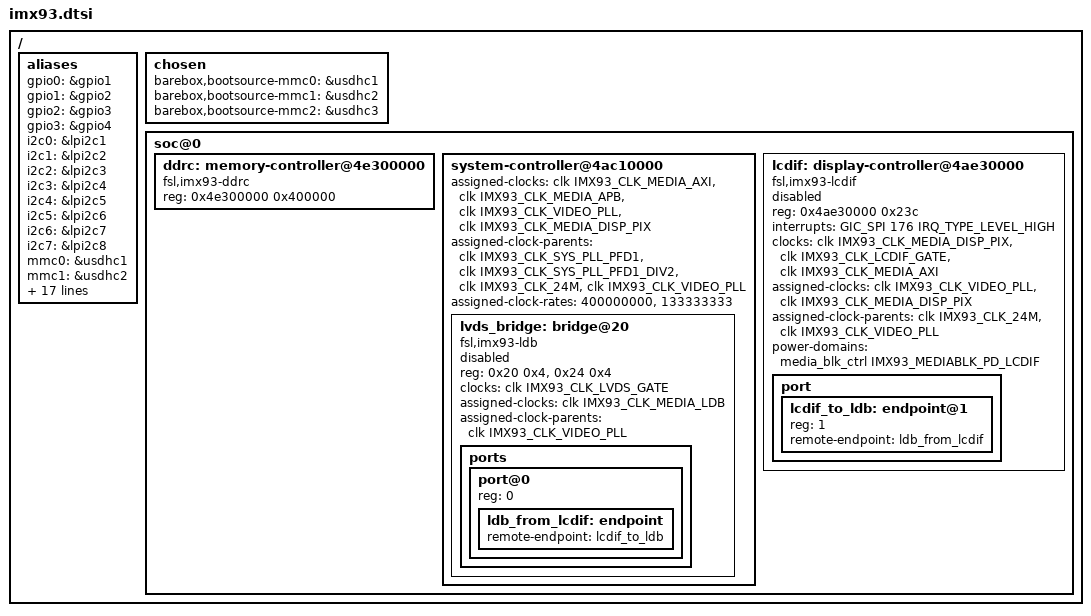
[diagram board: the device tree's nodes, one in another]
// SPDX-License-Identifier: (GPL-2.0+ OR MIT)
/ {
	aliases {
		gpio0 = &gpio1;
		gpio1 = &gpio2;
		gpio2 = &gpio3;
		gpio3 = &gpio4;
		i2c0 = &lpi2c1;
		i2c1 = &lpi2c2;
		i2c2 = &lpi2c3;
		i2c3 = &lpi2c4;
		i2c4 = &lpi2c5;
		i2c5 = &lpi2c6;
		i2c6 = &lpi2c7;
		i2c7 = &lpi2c8;
		mmc0 = &usdhc1;
		mmc1 = &usdhc2;
		mmc2 = &usdhc3;
		serial0 = &lpuart1;
		serial1 = &lpuart2;
		serial2 = &lpuart3;
		serial3 = &lpuart4;
		serial4 = &lpuart5;
		serial5 = &lpuart6;
		serial6 = &lpuart7;
		serial7 = &lpuart8;
		spi0 = &lpspi1;
		spi1 = &lpspi2;
		spi2 = &lpspi3;
		spi3 = &lpspi4;
		spi4 = &lpspi5;
		spi5 = &lpspi6;
		spi6 = &lpspi7;
		spi7 = &lpspi8;
	};

	chosen {
		barebox,bootsource-mmc0 = &usdhc1;
		barebox,bootsource-mmc1 = &usdhc2;
		barebox,bootsource-mmc2 = &usdhc3;
	};

	soc@0 {
		ddrc: memory-controller@4e300000 {
			compatible = "fsl,imx93-ddrc";
			reg = <0x4e300000 0x400000>;
		};

		system-controller@4ac10000 {
			#address-cells = <1>;
			#size-cells = <1>;
			assigned-clocks = <&clk IMX93_CLK_MEDIA_AXI>,
					  <&clk IMX93_CLK_MEDIA_APB>,
					  <&clk IMX93_CLK_VIDEO_PLL>,
					  <&clk IMX93_CLK_MEDIA_DISP_PIX>;
			assigned-clock-parents = <&clk IMX93_CLK_SYS_PLL_PFD1>,
						 <&clk IMX93_CLK_SYS_PLL_PFD1_DIV2>,
						 <&clk IMX93_CLK_24M>,
						 <&clk IMX93_CLK_VIDEO_PLL>;
			assigned-clock-rates = <400000000>, <133333333>;

			lvds_bridge: bridge@20 {
				compatible = "fsl,imx93-ldb";
				reg = <0x20 0x4>, <0x24 0x4>;
				reg-names = "ldb", "lvds";
				clocks = <&clk IMX93_CLK_LVDS_GATE>;
				clock-names = "ldb";
				assigned-clocks = <&clk IMX93_CLK_MEDIA_LDB>;
				assigned-clock-parents = <&clk IMX93_CLK_VIDEO_PLL>;
				status = "disabled";

				ports {
					#address-cells = <1>;
					#size-cells = <0>;

					port@0 {
						reg = <0>;

						ldb_from_lcdif: endpoint {
							remote-endpoint = <&lcdif_to_ldb>;
						};
					};
				};
			};
		};

		lcdif: display-controller@4ae30000 {
			compatible = "fsl,imx93-lcdif";
			reg = <0x4ae30000 0x23c>;
			interrupts = <GIC_SPI 176 IRQ_TYPE_LEVEL_HIGH>;
			clocks = <&clk IMX93_CLK_MEDIA_DISP_PIX>,
				 <&clk IMX93_CLK_LCDIF_GATE>,
				 <&clk IMX93_CLK_MEDIA_AXI>;
			clock-names = "pix", "axi", "disp_axi";
			assigned-clocks = <&clk IMX93_CLK_VIDEO_PLL>,
					  <&clk IMX93_CLK_MEDIA_DISP_PIX>;
			assigned-clock-parents = <&clk IMX93_CLK_24M>,
						 <&clk IMX93_CLK_VIDEO_PLL>;
			power-domains = <&media_blk_ctrl IMX93_MEDIABLK_PD_LCDIF>;
			status = "disabled";

			port {
				#address-cells = <1>;
				#size-cells = <0>;

				lcdif_to_ldb: endpoint@1 {
					reg = <1>;
					remote-endpoint = <&ldb_from_lcdif>;
				};
			};
		};
	};
};
